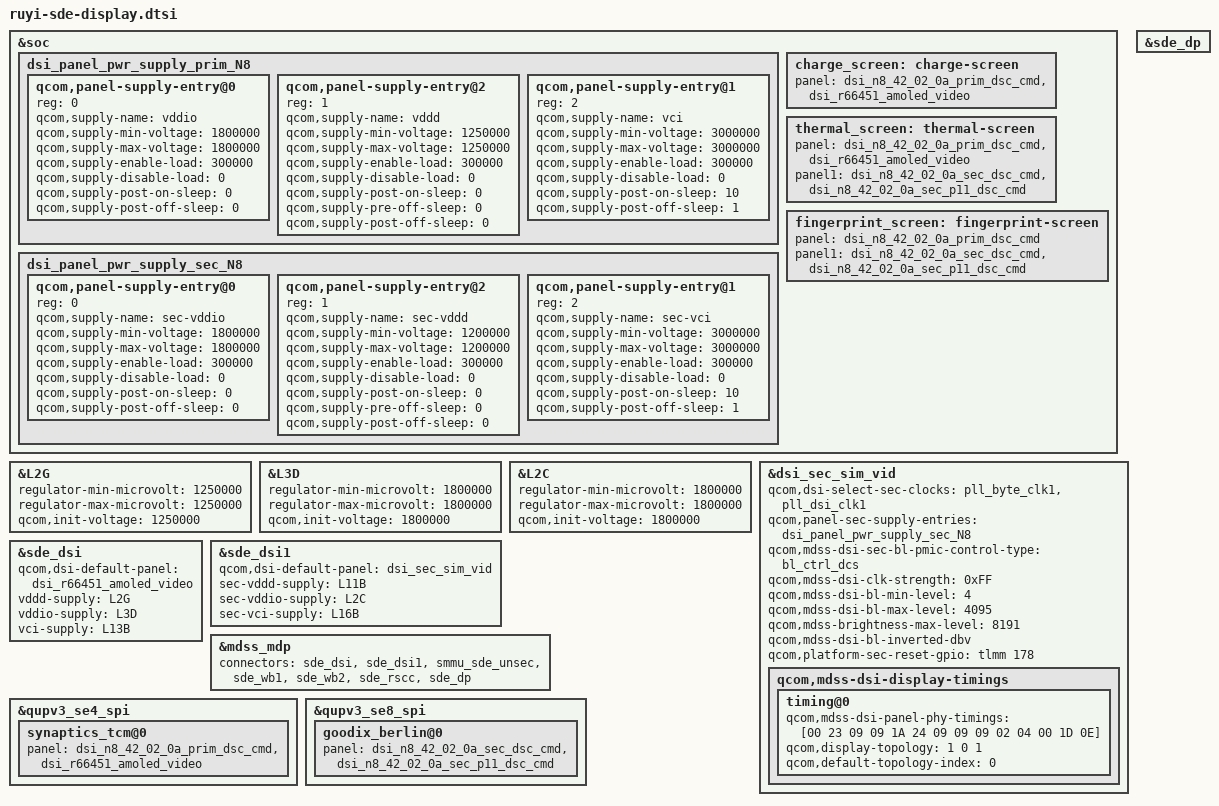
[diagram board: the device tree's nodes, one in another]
#include "pineapple-sde-display.dtsi"
#include "dsi-panel-n8-42-02-0a-prim-dsc-cmd.dtsi"
#include "dsi-panel-n8-42-02-0a-sec-dsc-cmd.dtsi"
#include "dsi-panel-n8-42-02-0a-sec-p11-dsc-cmd.dtsi"
#include "dsi-panel-r66451-dsc-fhd-plus-video.dtsi"
#include "dsi-panel-sec-sim-video.dtsi"

&soc {
	dsi_panel_pwr_supply_prim_N8: dsi_panel_pwr_supply_prim_N8 {
		qcom,panel-supply-entry@0 {
			reg = <0>;
			qcom,supply-name = "vddio";
			qcom,supply-min-voltage = <1800000>;
			qcom,supply-max-voltage = <1800000>;
			qcom,supply-enable-load = <300000>;
			qcom,supply-disable-load = <0>;
			qcom,supply-post-on-sleep = <0>;
			qcom,supply-post-off-sleep = <0>;
		};
		qcom,panel-supply-entry@2 {
			reg = <1>;
			qcom,supply-name = "vddd";
			qcom,supply-min-voltage = <1250000>;
			qcom,supply-max-voltage = <1250000>;
			qcom,supply-enable-load = <300000>;
			qcom,supply-disable-load = <0>;
			qcom,supply-post-on-sleep = <0>;
			qcom,supply-pre-off-sleep = <0>;
			qcom,supply-post-off-sleep = <0>;
		};
		qcom,panel-supply-entry@1 {
			reg = <2>;
			qcom,supply-name = "vci";
			qcom,supply-min-voltage = <3000000>;
			qcom,supply-max-voltage = <3000000>;
			qcom,supply-enable-load = <300000>;
			qcom,supply-disable-load = <0>;
			qcom,supply-post-on-sleep = <10>;
			qcom,supply-post-off-sleep = <1>;
		};
	};

	dsi_panel_pwr_supply_sec_N8: dsi_panel_pwr_supply_sec_N8 {
		qcom,panel-supply-entry@0 {
			reg = <0>;
			qcom,supply-name = "sec-vddio";
			qcom,supply-min-voltage = <1800000>;
			qcom,supply-max-voltage = <1800000>;
			qcom,supply-enable-load = <300000>;
			qcom,supply-disable-load = <0>;
			qcom,supply-post-on-sleep = <0>;
			qcom,supply-post-off-sleep = <0>;
		};
		qcom,panel-supply-entry@2 {
			reg = <1>;
			qcom,supply-name = "sec-vddd";
			qcom,supply-min-voltage = <1200000>;
			qcom,supply-max-voltage = <1200000>;
			qcom,supply-enable-load = <300000>;
			qcom,supply-disable-load = <0>;
			qcom,supply-post-on-sleep = <0>;
			qcom,supply-pre-off-sleep = <0>;
			qcom,supply-post-off-sleep = <0>;
		};
		qcom,panel-supply-entry@1 {
			reg = <2>;
			qcom,supply-name = "sec-vci";
			qcom,supply-min-voltage = <3000000>;
			qcom,supply-max-voltage = <3000000>;
			qcom,supply-enable-load = <300000>;
			qcom,supply-disable-load = <0>;
			qcom,supply-post-on-sleep = <10>;
			qcom,supply-post-off-sleep = <1>;
		};
	};
};

&L2G {
	regulator-min-microvolt = <1250000>;
	regulator-max-microvolt = <1250000>;
	qcom,init-voltage = <1250000>;
};

&L3D {
	regulator-min-microvolt = <1800000>;
	regulator-max-microvolt = <1800000>;
	qcom,init-voltage = <1800000>;
};
/*
&L11B {
	regulator-min-microvolt = <1200000>;
	regulator-max-microvolt = <1200000>;
	qcom,init-voltage = <1200000>;
};
*/
&L2C {
	regulator-min-microvolt = <1800000>;
	regulator-max-microvolt = <1800000>;
	qcom,init-voltage = <1800000>;
};

&dsi_sec_sim_vid {
	qcom,dsi-select-sec-clocks = "pll_byte_clk1", "pll_dsi_clk1";
	qcom,mdss-dsi-display-timings {
		timing@0 {
			/* 60hz */
			qcom,mdss-dsi-panel-phy-timings = [00 23 09 09 1A 24 09
				09 09 02 04 00 1D 0E];
			qcom,display-topology = <1 0 1>;
			qcom,default-topology-index = <0>;
		};
	};
};

&dsi_sec_sim_vid {
	qcom,panel-sec-supply-entries = <&dsi_panel_pwr_supply_sec_N8>;
	qcom,mdss-dsi-sec-bl-pmic-control-type = "bl_ctrl_dcs";
	qcom,mdss-dsi-clk-strength = <0xFF>;
	qcom,mdss-dsi-bl-min-level = <4>;
	qcom,mdss-dsi-bl-max-level = <4095>;
	qcom,mdss-brightness-max-level = <8191>;
	qcom,mdss-dsi-bl-inverted-dbv;
	qcom,platform-sec-reset-gpio = <&tlmm 178 0>;
};

&sde_dsi {
	qcom,dsi-default-panel = <&dsi_r66451_amoled_video>;
	vddd-supply = <&L2G>;
	vddio-supply = <&L3D>;
	vci-supply = <&L13B>;
};

&sde_dsi1 {
	qcom,dsi-default-panel = <&dsi_sec_sim_vid>;
	sec-vddd-supply = <&L11B>;
	sec-vddio-supply = <&L2C>;
	sec-vci-supply = <&L16B>;
};

&mdss_mdp {
	connectors = <&sde_dsi &sde_dsi1 &smmu_sde_unsec &sde_wb1 &sde_wb2 &sde_rscc &sde_dp>;
};

&sde_dp {
	status = "ok";
};

&qupv3_se4_spi {
	synaptics_tcm@0 {
		panel = <&dsi_n8_42_02_0a_prim_dsc_cmd
			&dsi_r66451_amoled_video>;
	};
};

&qupv3_se8_spi {
	goodix_berlin@0 {
		panel = <&dsi_n8_42_02_0a_sec_dsc_cmd
			&dsi_n8_42_02_0a_sec_p11_dsc_cmd>;
	};
};

&soc {
	charge_screen: charge-screen {
		panel  = <&dsi_n8_42_02_0a_prim_dsc_cmd
			&dsi_r66451_amoled_video>;
	};
};

&soc {
	thermal_screen: thermal-screen {
		panel = <&dsi_n8_42_02_0a_prim_dsc_cmd
			&dsi_r66451_amoled_video>;
		panel1 = <&dsi_n8_42_02_0a_sec_dsc_cmd
			 &dsi_n8_42_02_0a_sec_p11_dsc_cmd>;
	};
	fingerprint_screen: fingerprint-screen {
		panel = <&dsi_n8_42_02_0a_prim_dsc_cmd>;
		panel1 = <&dsi_n8_42_02_0a_sec_dsc_cmd
			 &dsi_n8_42_02_0a_sec_p11_dsc_cmd>;
	};
};
